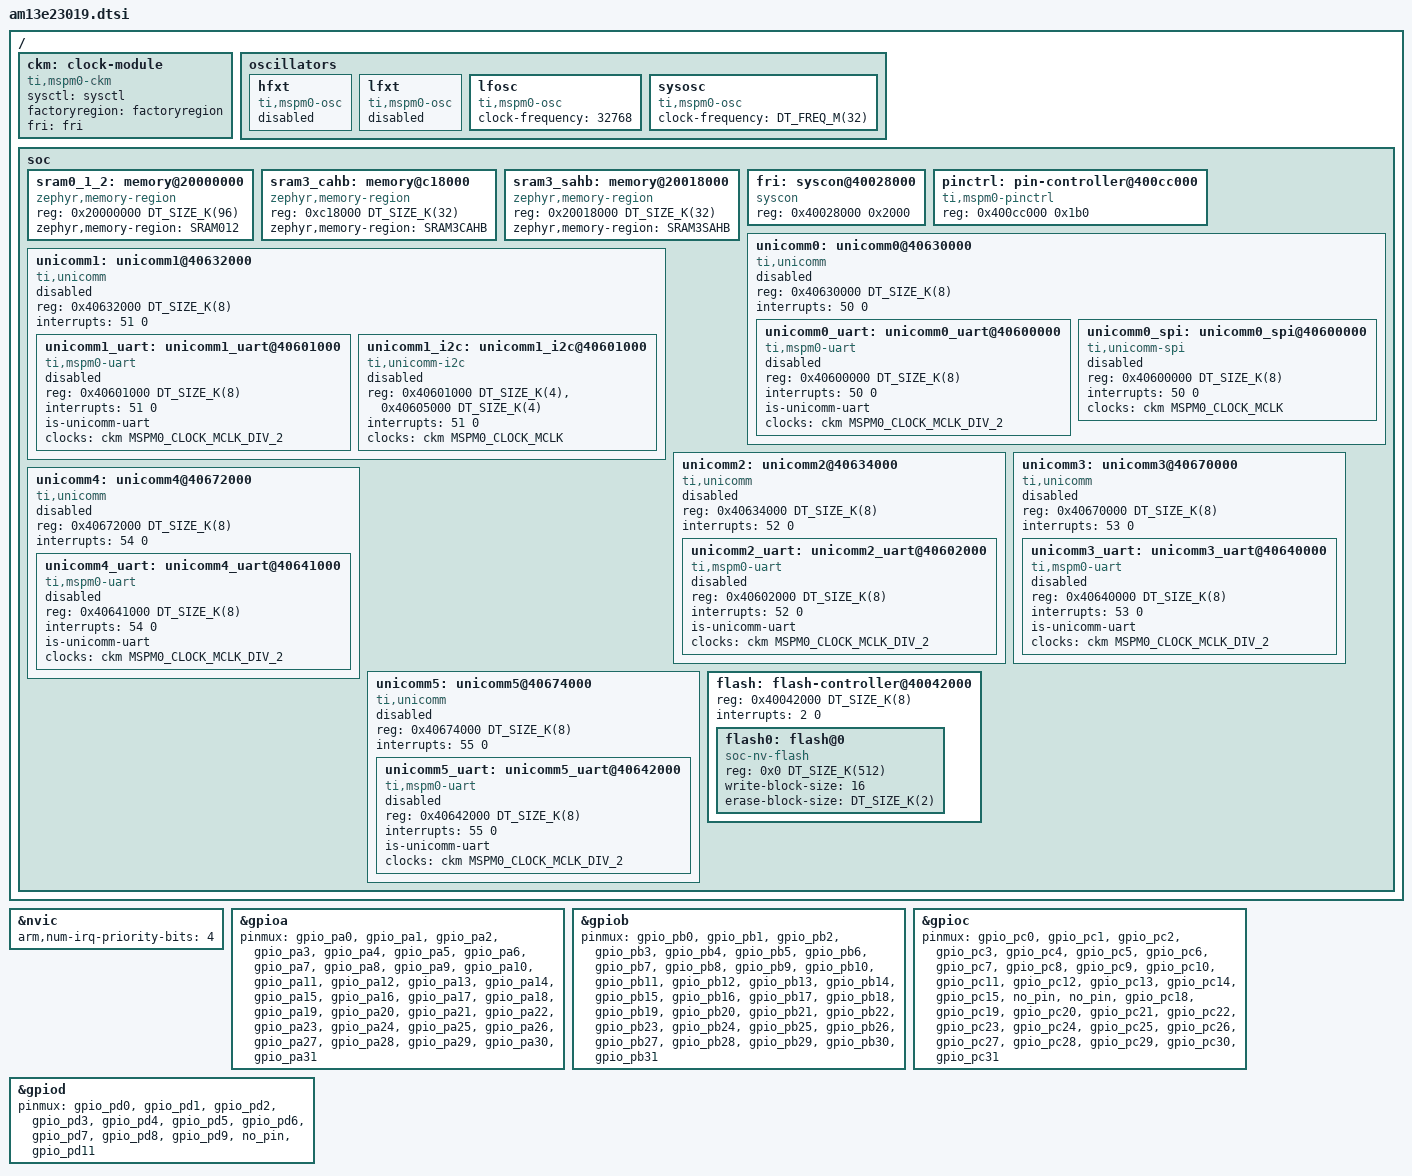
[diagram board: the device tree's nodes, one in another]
/*
 * Copyright (c) 2026 Texas Instruments Incorporated
 *
 * SPDX-License-Identifier: Apache-2.0
 */

#include "am13e.dtsi"
#include <zephyr/dt-bindings/clock/mspm0_clock.h>

/ {
	#address-cells = <1>;
	#size-cells = <1>;

	ckm: clock-module {
		compatible = "ti,mspm0-ckm";
		#clock-cells = <1>;
		sysctl = <&sysctl>;
		factoryregion = <&factoryregion>;
		fri = <&fri>;
	};

	oscillators: oscillators {
		hfxt: hfxt {
			#clock-cells = <0>;
			compatible = "ti,mspm0-osc";
			status = "disabled";
		};

		lfxt: lfxt {
			#clock-cells = <0>;
			compatible = "ti,mspm0-osc";
			status = "disabled";
		};

		lfosc: lfosc {
			#clock-cells = <0>;
			compatible = "ti,mspm0-osc";
			clock-frequency = <32768>;
		};

		sysosc: sysosc {
			#clock-cells = <0>;
			compatible = "ti,mspm0-osc";
			clock-frequency = <DT_FREQ_M(32)>;
		};
	};

	soc {
		sram0_1_2: memory@20000000 {
			compatible = "zephyr,memory-region";
			reg = <0x20000000 DT_SIZE_K(96)>;
			zephyr,memory-region = "SRAM012";
		};

		sram3_cahb: memory@c18000 {
			compatible = "zephyr,memory-region";
			reg = <0xc18000 DT_SIZE_K(32)>;
			zephyr,memory-region = "SRAM3CAHB";
		};

		sram3_sahb: memory@20018000 {
			compatible = "zephyr,memory-region";
			reg = <0x20018000 DT_SIZE_K(32)>;
			zephyr,memory-region = "SRAM3SAHB";
		};

		fri: syscon@40028000 {
			compatible = "syscon";
			reg = <0x40028000 0x2000>;
		};

		pinctrl: pin-controller@400cc000 {
			compatible = "ti,mspm0-pinctrl";
			reg = <0x400cc000 0x1b0>;
		};

		unicomm0: unicomm0@40630000 {
			reg = <0x40630000 DT_SIZE_K(8)>;
			compatible = "ti,unicomm";
			interrupts = <50 0>;
			#address-cells = <1>;
			#size-cells = <1>;
			status = "disabled";

			unicomm0_uart: unicomm0_uart@40600000 {
				reg = <0x40600000 DT_SIZE_K(8)>;
				interrupts = <50 0>;
				#address-cells = <1>;
				#size-cells = <1>;
				compatible = "ti,mspm0-uart";
				is-unicomm-uart;
				clocks = <&ckm MSPM0_CLOCK_MCLK_DIV_2>;
				status = "disabled";
			};

			/*
			 * UNICOMM0 as SPI — shares IP base with UART (same HW block,
			 * protocol selected via IPMODE). Verify reg address from TRM.
			 */
			unicomm0_spi: unicomm0_spi@40600000 {
				reg = <0x40600000 DT_SIZE_K(8)>;
				compatible = "ti,unicomm-spi";
				interrupts = <50 0>;
				#address-cells = <1>;
				#size-cells = <0>;
				clocks = <&ckm MSPM0_CLOCK_MCLK>;
				status = "disabled";
			};
		};

		unicomm1: unicomm1@40632000 {
			reg = <0x40632000 DT_SIZE_K(8)>;
			compatible = "ti,unicomm";
			interrupts = <51 0>;
			#address-cells = <1>;
			#size-cells = <1>;
			status = "disabled";

			unicomm1_uart: unicomm1_uart@40601000 {
				reg = <0x40601000 DT_SIZE_K(8)>;
				interrupts = <51 0>;
				#address-cells = <1>;
				#size-cells = <1>;
				compatible = "ti,mspm0-uart";
				is-unicomm-uart;
				clocks = <&ckm MSPM0_CLOCK_MCLK_DIV_2>;
				status = "disabled";
			};

			/*
			 * UNICOMM1 as I2C — controller + target share UNICOMM1 IP.
			 * reg-names "controller"/"target" with +0x1000 driver offset.
			 * Verify both addresses from AM13E TRM Section (I2C).
			 */
			unicomm1_i2c: unicomm1_i2c@40601000 {
				compatible = "ti,unicomm-i2c";
				reg = <0x40601000 DT_SIZE_K(4)>,
				      <0x40605000 DT_SIZE_K(4)>;
				reg-names = "controller", "target";
				interrupts = <51 0>;
				#address-cells = <1>;
				#size-cells = <0>;
				clocks = <&ckm MSPM0_CLOCK_MCLK>;
				status = "disabled";
			};
		};

		unicomm2: unicomm2@40634000 {
			reg = <0x40634000 DT_SIZE_K(8)>;
			compatible = "ti,unicomm";
			interrupts = <52 0>;
			#address-cells = <1>;
			#size-cells = <1>;
			status = "disabled";

			unicomm2_uart: unicomm2_uart@40602000 {
				reg = <0x40602000 DT_SIZE_K(8)>;
				interrupts = <52 0>;
				#address-cells = <1>;
				#size-cells = <1>;
				compatible = "ti,mspm0-uart";
				is-unicomm-uart;
				clocks = <&ckm MSPM0_CLOCK_MCLK_DIV_2>;
				status = "disabled";
			};
		};

		unicomm3: unicomm3@40670000 {
			reg = <0x40670000 DT_SIZE_K(8)>;
			compatible = "ti,unicomm";
			interrupts = <53 0>;
			#address-cells = <1>;
			#size-cells = <1>;
			status = "disabled";

			unicomm3_uart: unicomm3_uart@40640000 {
				reg = <0x40640000 DT_SIZE_K(8)>;
				interrupts = <53 0>;
				#address-cells = <1>;
				#size-cells = <1>;
				compatible = "ti,mspm0-uart";
				is-unicomm-uart;
				clocks = <&ckm MSPM0_CLOCK_MCLK_DIV_2>;
				status = "disabled";
			};
		};

		unicomm4: unicomm4@40672000 {
			reg = <0x40672000 DT_SIZE_K(8)>;
			compatible = "ti,unicomm";
			interrupts = <54 0>;
			#address-cells = <1>;
			#size-cells = <1>;
			status = "disabled";

			unicomm4_uart: unicomm4_uart@40641000 {
				reg = <0x40641000 DT_SIZE_K(8)>;
				interrupts = <54 0>;
				#address-cells = <1>;
				#size-cells = <1>;
				compatible = "ti,mspm0-uart";
				is-unicomm-uart;
				clocks = <&ckm MSPM0_CLOCK_MCLK_DIV_2>;
				status = "disabled";
			};
		};

		unicomm5: unicomm5@40674000 {
			reg = <0x40674000 DT_SIZE_K(8)>;
			compatible = "ti,unicomm";
			interrupts = <55 0>;
			#address-cells = <1>;
			#size-cells = <1>;
			status = "disabled";

			unicomm5_uart: unicomm5_uart@40642000 {
				reg = <0x40642000 DT_SIZE_K(8)>;
				interrupts = <55 0>;
				#address-cells = <1>;
				#size-cells = <1>;
				compatible = "ti,mspm0-uart";
				is-unicomm-uart;
				clocks = <&ckm MSPM0_CLOCK_MCLK_DIV_2>;
				status = "disabled";
			};
		};

		flash: flash-controller@40042000 {
			reg = <0x40042000 DT_SIZE_K(8)>;
			ranges;
			interrupts = <2 0>;

			#address-cells = <1>;
			#size-cells = <1>;

			flash0: flash@0 {
				compatible = "soc-nv-flash";
				reg = <0x0 DT_SIZE_K(512)>;
				ranges = <0x0 0x0 DT_SIZE_K(512)>;

				write-block-size = <16>;
				erase-block-size = <DT_SIZE_K(2)>;

				#address-cells = <1>;
				#size-cells = <1>;
			};
		};
	};
};

&nvic {
	arm,num-irq-priority-bits = <4>;
};

/* GPIO pin-to-PINCM maps (from AM13E23019 datasheet + pinctrl DTSI).
 * GPIO0=PA, GPIO1=PB, GPIO2=PC, GPIO3=PD. PINCM is 1-based: PA0=PINCM1.
 * &no_pin marks package-absent pins: PC16, PC17, PD10.
 */
&gpioa {
	pinmux = <&gpio_pa0>,
		 <&gpio_pa1>,
		 <&gpio_pa2>,
		 <&gpio_pa3>,
		 <&gpio_pa4>,
		 <&gpio_pa5>,
		 <&gpio_pa6>,
		 <&gpio_pa7>,
		 <&gpio_pa8>,
		 <&gpio_pa9>,
		 <&gpio_pa10>,
		 <&gpio_pa11>,
		 <&gpio_pa12>,
		 <&gpio_pa13>,
		 <&gpio_pa14>,
		 <&gpio_pa15>,
		 <&gpio_pa16>,
		 <&gpio_pa17>,
		 <&gpio_pa18>,
		 <&gpio_pa19>,
		 <&gpio_pa20>,
		 <&gpio_pa21>,
		 <&gpio_pa22>,
		 <&gpio_pa23>,
		 <&gpio_pa24>,
		 <&gpio_pa25>,
		 <&gpio_pa26>,
		 <&gpio_pa27>,
		 <&gpio_pa28>,
		 <&gpio_pa29>,
		 <&gpio_pa30>,
		 <&gpio_pa31>;
};

&gpiob {
	pinmux = <&gpio_pb0>,
		 <&gpio_pb1>,
		 <&gpio_pb2>,
		 <&gpio_pb3>,
		 <&gpio_pb4>,
		 <&gpio_pb5>,
		 <&gpio_pb6>,
		 <&gpio_pb7>,
		 <&gpio_pb8>,
		 <&gpio_pb9>,
		 <&gpio_pb10>,
		 <&gpio_pb11>,
		 <&gpio_pb12>,
		 <&gpio_pb13>,
		 <&gpio_pb14>,
		 <&gpio_pb15>,
		 <&gpio_pb16>,
		 <&gpio_pb17>,
		 <&gpio_pb18>,
		 <&gpio_pb19>,
		 <&gpio_pb20>,
		 <&gpio_pb21>,
		 <&gpio_pb22>,
		 <&gpio_pb23>,
		 <&gpio_pb24>,
		 <&gpio_pb25>,
		 <&gpio_pb26>,
		 <&gpio_pb27>,
		 <&gpio_pb28>,
		 <&gpio_pb29>,
		 <&gpio_pb30>,
		 <&gpio_pb31>;
};

&gpioc {
	pinmux = <&gpio_pc0>,
		 <&gpio_pc1>,
		 <&gpio_pc2>,
		 <&gpio_pc3>,
		 <&gpio_pc4>,
		 <&gpio_pc5>,
		 <&gpio_pc6>,
		 <&gpio_pc7>,
		 <&gpio_pc8>,
		 <&gpio_pc9>,
		 <&gpio_pc10>,
		 <&gpio_pc11>,
		 <&gpio_pc12>,
		 <&gpio_pc13>,
		 <&gpio_pc14>,
		 <&gpio_pc15>,
		 <&no_pin>,		/* PC16: not bonded */
		 <&no_pin>,		/* PC17: not bonded */
		 <&gpio_pc18>,
		 <&gpio_pc19>,
		 <&gpio_pc20>,
		 <&gpio_pc21>,
		 <&gpio_pc22>,
		 <&gpio_pc23>,
		 <&gpio_pc24>,
		 <&gpio_pc25>,
		 <&gpio_pc26>,
		 <&gpio_pc27>,
		 <&gpio_pc28>,
		 <&gpio_pc29>,
		 <&gpio_pc30>,
		 <&gpio_pc31>;
};

&gpiod {
	pinmux = <&gpio_pd0>,
		 <&gpio_pd1>,
		 <&gpio_pd2>,
		 <&gpio_pd3>,
		 <&gpio_pd4>,
		 <&gpio_pd5>,
		 <&gpio_pd6>,
		 <&gpio_pd7>,
		 <&gpio_pd8>,
		 <&gpio_pd9>,
		 <&no_pin>,		/* PD10: not bonded */
		 <&gpio_pd11>;
};
